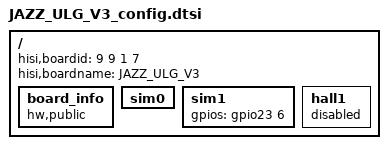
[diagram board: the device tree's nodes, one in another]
/*
 * Hisilicon Ltd.
 *
 * A15x4 A7x4
 *
 * It is only a demo for hisilicon hi3630 board. You show change the
 * address of each node according to datasheet.
 */


/include/ "JAZZ_ULG_V1_config.dtsi"

/ {
	hisi,boardid = <9 9 1 7>;
	hisi,boardname = "JAZZ_ULG_V3";
	board_info: board_info {
		hw,public;
	};
	sim0 {
		status = "ok";
	};
	sim1 {
		gpios = <&gpio23 6 0>;
		status = "ok";
	};

	hall1 {
		status = "disabled";
	};
};
